# SERDES_10G0 register map
Vendor: Texas Instruments
Registers are 32-bit, read-write, reset 0x0 unless marked. A register's access mark holds for its fields unless they carry their own. Offsets are as the file gives them; [hi:lo] are bit positions.

## SERDES_10G0 (part 4 of 5)
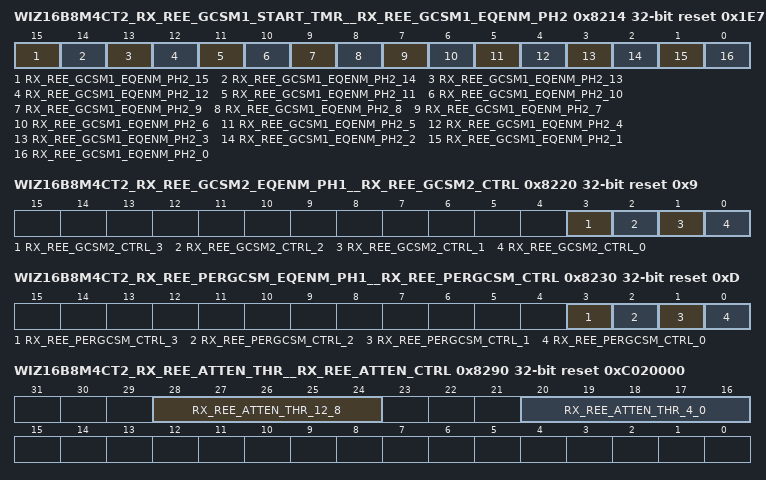
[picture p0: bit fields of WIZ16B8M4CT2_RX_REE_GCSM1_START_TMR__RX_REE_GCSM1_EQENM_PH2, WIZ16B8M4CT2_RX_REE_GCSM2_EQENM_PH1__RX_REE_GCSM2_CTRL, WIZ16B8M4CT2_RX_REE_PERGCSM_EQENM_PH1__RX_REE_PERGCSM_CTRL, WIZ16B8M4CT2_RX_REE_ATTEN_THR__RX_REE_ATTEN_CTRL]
0x8214 WIZ16B8M4CT2_RX_REE_GCSM1_START_TMR__RX_REE_GCSM1_EQENM_PH2 reset 0x1E7 — REE general control state machine 1 phase 2 equalization enable mask register
  [15] RX_REE_GCSM1_EQENM_PH2_15 — Reserved - spare
  [14] RX_REE_GCSM1_EQENM_PH2_14 — Ignore 1010 controller : When set to 1'b1, this function is enabled when the general control state machine 1 is controlling the REE.
  [13] RX_REE_GCSM1_EQENM_PH2_13 — TX equalization evaluator : When set to 1'b1, this function is enabled when the general control state machine 1 is controlling the REE.
  [12] RX_REE_GCSM1_EQENM_PH2_12 — TX post cursor control : When set to 1'b1, this function is enabled when the general control state machine 1 is controlling the REE.
  [11] RX_REE_GCSM1_EQENM_PH2_11 — TX pre cursor control : When set to 1'b1, this function is enabled when the general control state machine 1 is controlling the REE.
  [10] RX_REE_GCSM1_EQENM_PH2_10 — Short channel correction : When set to 1'b1, this function is enabled when the general control state machine 1 is controlling the REE.
  [9] RX_REE_GCSM1_EQENM_PH2_9 — RX attenuation : When set to 1'b1, this function is enabled when the general control state machine 1 is controlling the REE.
  [8] RX_REE_GCSM1_EQENM_PH2_8 — RX VGA gain : When set to 1'b1, this function is enabled when the general control state machine 1 is controlling the REE.
  [7] RX_REE_GCSM1_EQENM_PH2_7 — RX offset correction coefficient : When set to 1'b1, this function is enabled when the general control state machine 1 is controlling the REE.
  [6] RX_REE_GCSM1_EQENM_PH2_6 — RX peaking amp gain : When set to 1'b1, this function is enabled when the general control state machine 1 is controlling the REE.
  [5] RX_REE_GCSM1_EQENM_PH2_5 — RX low frequency equalizer adaptive control : When set to 1'b1, this function is enabled when the general control state machine 1 is controlling the REE.
  [4] RX_REE_GCSM1_EQENM_PH2_4 — Reserved - spare
  [3] RX_REE_GCSM1_EQENM_PH2_3 — Reserved - spare
  [2] RX_REE_GCSM1_EQENM_PH2_2 — RX tap 3 : When set to 1'b1, this function is enabled when the general control state machine 1 is controlling the REE.
  [1] RX_REE_GCSM1_EQENM_PH2_1 — RX tap 2 : When set to 1'b1, this function is enabled when the general control state machine 1 is controlling the REE.
  [0] RX_REE_GCSM1_EQENM_PH2_0 — RX tap 1 : When set to 1'b1, this function is enabled when the general control state machine 1 is controlling the REE.
0x8220 WIZ16B8M4CT2_RX_REE_GCSM2_EQENM_PH1__RX_REE_GCSM2_CTRL reset 0x9 — REE general control state machine 2 control register
  [3] RX_REE_GCSM2_CTRL_3 — Equalization function reset enable: Enables the reset of the functions controlled by this state machine, using the rx_ree_fcn_reset_n signal, when the equalization mode changes. 1'b1 : Enabled 1'b0 : Disabled
  [2] RX_REE_GCSM2_CTRL_2 — Loop enable: Controls when the equalization functions in this state machine are run one time or loop continuously.
  [1] RX_REE_GCSM2_CTRL_1 — Force run equalization: Setting this bit to a 1'b1, will force the general control state machine to run, independent of the macro functions that normally run the equalization.
  [0] RX_REE_GCSM2_CTRL_0 — Enable: This bit enables the general control state machine function. 1'b1 : Enabled 1'b0 : Disabled
0x8230 WIZ16B8M4CT2_RX_REE_PERGCSM_EQENM_PH1__RX_REE_PERGCSM_CTRL reset 0xD — REE periodic general control state machine control register
  [3] RX_REE_PERGCSM_CTRL_3 — Equalization function reset enable: Enables the reset of the functions controlled by this state machine, using the rx_ree_fcn_reset_n pin, when the equalization mode changes. 1'b1 : Enabled 1'b0 : Disabled
  [2] RX_REE_PERGCSM_CTRL_2 — Loop enable: Controls when the equalization functions in this state machine are run one time or loop continuously.
  [1] RX_REE_PERGCSM_CTRL_1 — Force run equalization: Setting this bit to a 1'b1, will force the general control state machine to run, independent of the macro functions that normally run the equalization.
  [0] RX_REE_PERGCSM_CTRL_0 — Enable: This bit enables the general control state machine function. 1'b1 : Enabled 1'b0 : Disabled
0x8290 WIZ16B8M4CT2_RX_REE_ATTEN_THR__RX_REE_ATTEN_CTRL reset 0xC020000 — REE attenuation control register (!)
  [28:24] RX_REE_ATTEN_THR_12_8 — Attenuation high threshold value: High threshold value to compare against the VGA gain accumulator value. Note that the value on this field is not a twos complement value (There is no sign bit and it is always a positive number).
  [20:16] RX_REE_ATTEN_THR_4_0 — Attenuation low threshold value: Low threshold value to compare against the VGA gain accumulator value. Note that the value on this field is not a twos complement value (There is no sign bit and it is always a positive number).
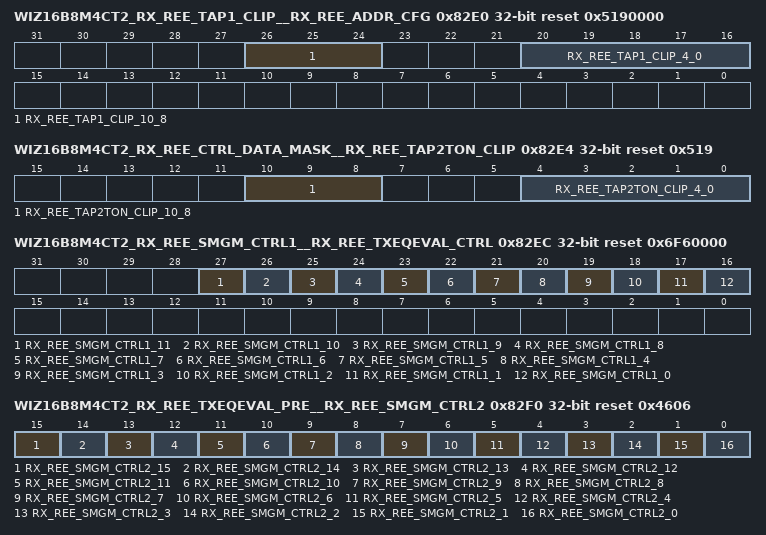
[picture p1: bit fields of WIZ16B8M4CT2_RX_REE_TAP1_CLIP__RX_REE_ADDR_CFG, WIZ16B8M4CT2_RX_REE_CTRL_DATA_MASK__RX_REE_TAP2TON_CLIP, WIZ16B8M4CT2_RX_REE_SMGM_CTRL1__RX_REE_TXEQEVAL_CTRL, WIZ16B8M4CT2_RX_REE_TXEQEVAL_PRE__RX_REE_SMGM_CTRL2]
0x82E0 WIZ16B8M4CT2_RX_REE_TAP1_CLIP__RX_REE_ADDR_CFG reset 0x5190000 — REE adder configuration register (!)
  [26:24] RX_REE_TAP1_CLIP_10_8 — VGA target gain adjust multiplier: Controls how much to multiply the VGA target gain adjust by, when calculating the tap threshold. The following are valid values, and the corresponding multiplier values. 3'b000 : x 0.00 3'b001 : x 0.25 3'b010 : x 0.50 3'b011 : x 0.75 3'b100 : x 1.00 3'b101 : x 1.25 3'b110 : x 1.50 3'b111 : x 1.75 Note : By setting this field to 3'b000, the threshold value of the tap can be directly controlled by the threshold adjust field in this register. Note : The VGA gain adjust signal is always a negative number.
  [20:16] RX_REE_TAP1_CLIP_4_0 — Threshold adjust: Controls how much the threshold can be adjusted by, after multiplying the VGA target gain adjust multiplier with the VGA target gain adjust. Note that this field is a positive number (not twos complement). Note : This field must not be set to a value of 0. Note : The combination of the multiplier and threshold fields in this register controls the positive and negative thresholds for the taps, according to the following equation. Note that the logic associated with this limits the range of the magnitude to 0 to 31, before creating the positive and negative thresholds. +/- ((VGA target gain adjust * VGA target gain adjust multiplier) + Threshold adjust)
0x82E4 WIZ16B8M4CT2_RX_REE_CTRL_DATA_MASK__RX_REE_TAP2TON_CLIP reset 0x519 — REE taps 2 and 3 clip control register (!)
  [10:8] RX_REE_TAP2TON_CLIP_10_8 — VGA target gain adjust multiplier: Controls how much to multiply the VGA target gain adjust by, when calculating the tap threshold. The following are valid values, and the corresponding multiplier values. 3'b000 : x 0.00 3'b001 : x 0.25 3'b010 : x 0.50 3'b011 : x 0.75 3'b100 : x 1.00 3'b101 : x 1.25 3'b110 : x 1.50 3'b111 : x 1.75 Note : By setting this field to 3'b000, the threshold value of the tap can be directly controlled by the threshold adjust field in this register.
  [4:0] RX_REE_TAP2TON_CLIP_4_0 — Threshold adjust: Controls how much the threshold can be adjusted by, after multiplying the VGA target gain adjust multiplier with the VGA target gain adjust. Note that this field is a positive number (not twos complement). Note : This field must not be set to a value of 0. Note : The combination of the multiplier and threshold fields in this register controls the positive and negative thresholds for the taps, according to the following equation. Note that the logic associated with this limits the range of the magnitude to 0 to 31, before creating the positive and negative thresholds. +/- ((VGA target gain adjust * VGA target gain adjust multiplier) + Threshold adjust)
0x82EC WIZ16B8M4CT2_RX_REE_SMGM_CTRL1__RX_REE_TXEQEVAL_CTRL reset 0x6F60000 — REE TX equalization evaluator control register (!)
  [27] RX_REE_SMGM_CTRL1_11 — REE Periodic general control state machine enable standard mode 3: This bit will control if the REE periodic general control state machine will run, when xcvr_standard_mode is set to 2'b11. 1'b0 : Disabled 1'b1 : Enabled
  [26] RX_REE_SMGM_CTRL1_10 — REE Periodic general control state machine enable standard mode 2: This bit will control if the REE periodic general control state machine will run, when xcvr_standard_mode is set to 2'b10. 1'b0 : Disabled 1'b1 : Enabled
  [25] RX_REE_SMGM_CTRL1_9 — REE Periodic general control state machine enable standard mode 1: This bit will control if the REE periodic general control state machine will run, when xcvr_standard_mode is set to 2'b01. 1'b0 : Disabled 1'b1 : Enabled
  [24] RX_REE_SMGM_CTRL1_8 — REE Periodic general control state machine enable standard mode 0: This bit will control if the REE periodic general control state machine will run, when xcvr_standard_mode is set to 2'b00. 1'b0 : Disabled 1'b1 : Enabled
  [23] RX_REE_SMGM_CTRL1_7 — REE general control state machine 2 enable standard mode 3: This bit will control if the REE general control state machine 2 will run, when xcvr_standard_mode is set to 2'b11. 1'b0 : Disabled 1'b1 : Enabled
  [22] RX_REE_SMGM_CTRL1_6 — REE general control state machine 2 enable standard mode 2: This bit will control if the REE general control state machine 2 will run, when xcvr_standard_mode is set to 2'b10. 1'b0 : Disabled 1'b1 : Enabled
  [21] RX_REE_SMGM_CTRL1_5 — REE general control state machine 2 enable standard mode 1: This bit will control if the REE general control state machine 2 will run, when xcvr_standard_mode is set to 2'b01. 1'b0 : Disabled 1'b1 : Enabled
  [20] RX_REE_SMGM_CTRL1_4 — REE general control state machine 2 enable standard mode 0: This bit will control if the REE general control state machine 2 will run, when xcvr_standard_mode is set to 2'b00. 1'b0 : Disabled 1'b1 : Enabled
  [19] RX_REE_SMGM_CTRL1_3 — REE general control state machine 1 enable standard mode 3: This bit will control if the REE general control state machine 1 will run, when xcvr_standard_mode is set to 2'b11. 1'b0 : Disabled 1'b1 : Enabled
  [18] RX_REE_SMGM_CTRL1_2 — REE general control state machine 1 enable standard mode 2: This bit will control if the REE general control state machine 1 will run, when xcvr_standard_mode is set to 2'b10. 1'b0 : Disabled 1'b1 : Enabled
  [17] RX_REE_SMGM_CTRL1_1 — REE general control state machine 1 enable standard mode 1: This bit will control if the REE general control state machine 1 will run, when xcvr_standard_mode is set to 2'b01. 1'b0 : Disabled 1'b1 : Enabled
  [16] RX_REE_SMGM_CTRL1_0 — REE general control state machine 1 enable standard mode 0: This bit will control if the REE general control state machine 1 will run, when xcvr_standard_mode is set to 2'b00. 1'b0 : Disabled 1'b1 : Enabled
0x82F0 WIZ16B8M4CT2_RX_REE_TXEQEVAL_PRE__RX_REE_SMGM_CTRL2 reset 0x4606 — REE control state machine gen mode control register 2 (!)
  [15] RX_REE_SMGM_CTRL2_15 — REE PCIe Gen 3 TX equalization state machine E path en standard mode 3: This bit controls if the REE PCIE Gen 3 TX equalization state machine will enable the analog E path when xcvr_standard_mode is set to 2'b11. 1'b0 : Disabled 1'b1 : Enabled
  [14] RX_REE_SMGM_CTRL2_14 — REE PCIe Gen 3 TX equalization state machine E path en standard mode 2: This bit controls if the REE PCIE Gen 3 TX equalization state machine will enable the analog E path when xcvr_standard_mode is set to 2'b10. 1'b0 : Disabled 1'b1 : Enabled
  [13] RX_REE_SMGM_CTRL2_13 — REE PCIe Gen 3 TX equalization state machine E path en standard mode 1: This bit controls if the REE PCIE Gen 3 TX equalization state machine will enable the analog E path when xcvr_standard_mode is set to 2'b01. 1'b0 : Disabled 1'b1 : Enabled
  [12] RX_REE_SMGM_CTRL2_12 — REE PCIe Gen 3 TX equalization state machine E path en standard mode 0: This bit controls if the REE PCIE Gen 3 TX equalization state machine will enable the analog E path when xcvr_standard_mode is set to 2'b00. 1'b0 : Disabled 1'b1 : Enabled
  [11] RX_REE_SMGM_CTRL2_11 — REE Periodic general control state machine E path en standard mode 3: This bit controls if the REE periodic general control state machine will enable the analog E path when xcvr_standard_mode is set to 2'b11. 1'b0 : Disabled 1'b1 : Enabled
  [10] RX_REE_SMGM_CTRL2_10 — REE Periodic general control state machine E path en standard mode 2: This bit controls if the REE periodic general control state machine will enable the analog E path when xcvr_standard_mode is set to 2'b10. 1'b0 : Disabled 1'b1 : Enabled
  [9] RX_REE_SMGM_CTRL2_9 — REE Periodic general control state machine E path en standard mode 1: This bit controls if the REE periodic general control state machine will enable the analog E path when xcvr_standard_mode is set to 2'b01. 1'b0 : Disabled 1'b1 : Enabled
  [8] RX_REE_SMGM_CTRL2_8 — REE Periodic general control state machine E path en standard mode 0: This bit controls if the REE periodic general control state machine will enable the analog E path when xcvr_standard_mode is set to 2'b00. 1'b0 : Disabled 1'b1 : Enabled
  [7] RX_REE_SMGM_CTRL2_7 — REE general control state machine 2 E path en standard mode 3: This bit controls if the REE general control state machine 2 will enable the analog E path when xcvr_standard_mode is set to 2'b11. 1'b0 : Disabled 1'b1 : Enabled
  [6] RX_REE_SMGM_CTRL2_6 — REE general control state machine 2 E path en standard mode 2: This bit controls if the REE general control state machine 2 will enable the analog E path when xcvr_standard_mode is set to 2'b10. 1'b0 : Disabled 1'b1 : Enabled
  [5] RX_REE_SMGM_CTRL2_5 — REE general control state machine 2 E path en standard mode 1: This bit controls if the REE general control state machine 2 will enable the analog E path when xcvr_standard_mode is set to 2'b01. 1'b0 : Disabled 1'b1 : Enabled
  [4] RX_REE_SMGM_CTRL2_4 — REE general control state machine 2 E path en standard mode 0: This bit controls if the REE general control state machine 2 will enable the analog E path when xcvr_standard_mode is set to 2'b00. 1'b0 : Disabled 1'b1 : Enabled
  [3] RX_REE_SMGM_CTRL2_3 — REE general control state machine 1 E path en standard mode 3: This bit controls if the REE general control state machine 1 will enable the analog E path when xcvr_standard_mode is set to 2'b11. 1'b0 : Disabled 1'b1 : Enabled
  [2] RX_REE_SMGM_CTRL2_2 — REE general control state machine 1 E path en standard mode 2: This bit controls if the REE general control state machine 1 will enable the analog E path when xcvr_standard_mode is set to 2'b10. 1'b0 : Disabled 1'b1 : Enabled
  [1] RX_REE_SMGM_CTRL2_1 — REE general control state machine 1 E path en standard mode 1: This bit controls if the REE general control state machine 1 will enable the analog E path when xcvr_standard_mode is set to 2'b01. 1'b0 : Disabled 1'b1 : Enabled
  [0] RX_REE_SMGM_CTRL2_0 — REE general control state machine 1 E path en standard mode 0: This bit controls if the REE general control state machine 1 will enable the analog E path when xcvr_standard_mode is set to 2'b00. 1'b0 : Disabled 1'b1 : Enabled
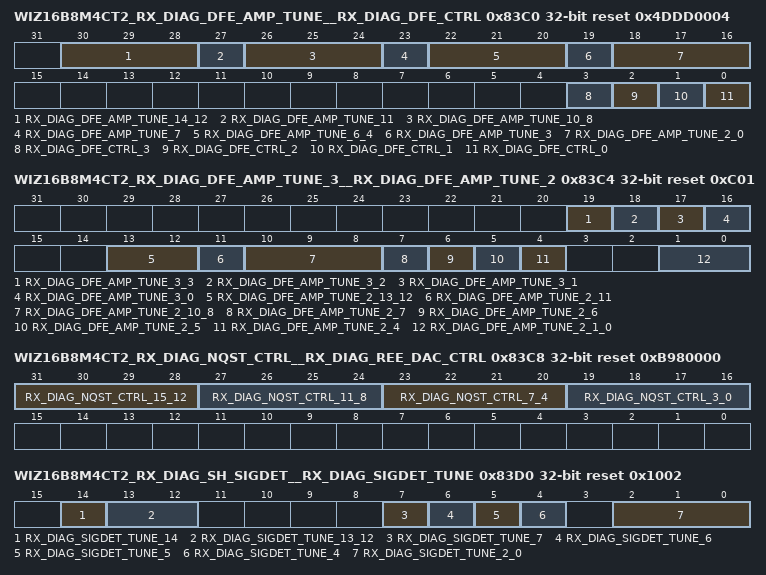
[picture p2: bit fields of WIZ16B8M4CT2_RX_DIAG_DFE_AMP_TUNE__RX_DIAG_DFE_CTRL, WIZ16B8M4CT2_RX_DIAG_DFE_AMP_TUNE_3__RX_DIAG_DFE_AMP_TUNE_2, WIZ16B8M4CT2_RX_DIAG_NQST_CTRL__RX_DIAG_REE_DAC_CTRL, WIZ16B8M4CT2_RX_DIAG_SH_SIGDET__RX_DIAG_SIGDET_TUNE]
0x83C0 WIZ16B8M4CT2_RX_DIAG_DFE_AMP_TUNE__RX_DIAG_DFE_CTRL reset 0x4DDD0004 — Receiver DFE control register (!)
  [30:28] RX_DIAG_DFE_AMP_TUNE_14_12 — DFE constant gm bias tune: Adjusts the constant gm bias. 3'b000: -34 uA 3'b001 3'b010 3'b011 3'b100: - 50 uA 3'b101 3'b110 3'b111: -62 uA
  [27] RX_DIAG_DFE_AMP_TUNE_11 — DFE VGA constant gm bias enable: Enables the VGA constant gm bias. This bit drives the rxda_vga_cnst_gm_en signal going to the analog. 1'b0 : Disabled. 1'b1 : Enabled.
  [26:24] RX_DIAG_DFE_AMP_TUNE_10_8 — DFE VGA amp current adjust: Adjusts the current for the DFE VGA amp, using the rxda_vga_current_adj signal, as specified below. Note that the percentages are approximate values. 3'b000: +30% (maximum) ... 3'b101: 0% ... 3'b111: -30% (minimum)
  [23] RX_DIAG_DFE_AMP_TUNE_7 — DFE peaking constant gm bias enable: Enables the peaking constant gm bias. This bit drives the rxda_peak_cnst_gm_en signal going to the analog. 1'b0 : Disabled. 1'b1 : Enabled.
  [22:20] RX_DIAG_DFE_AMP_TUNE_6_4 — DFE peaking amp current adjust: Adjusts the current for the DFE peaking amp, using the rxda_peak_current_adj signal, as specified below. Note that the percentages are approximate values. 3'b000: +30% (maximum) ... 3'b101: 0% ... 3'b111: -30% (minimum)
  [19] RX_DIAG_DFE_AMP_TUNE_3 — DFE summing constant gm bias enable: Enables the summing constant gm bias. This bit drives the rxda_sum_cnst_gm_en signal going to the analog. 1'b0 : Disabled. 1'b1 : Enabled.
  [18:16] RX_DIAG_DFE_AMP_TUNE_2_0 — DFE summing amp current adjust: Adjusts the current for the DFE summing amp, using the rxda_sum_current_adj signal, as specified below. Note that the percentages are approximate values. 3'b000: +30% (maximum) ... 3'b101: 0% ... 3'b111: -30% (minimum)
  [3] RX_DIAG_DFE_CTRL_3 — Receiver DFE low frequency equalization enable value standard mode 3: This bit controls the rxda_dfe_lfeq_en signal going to the analog, which is used to enable the receiver DFE low frequency equalization analog circuits, when xcvr_standard_mode is set to 2'b11. 1'b0 : Disabled 1'b1 : Enabled
  [2] RX_DIAG_DFE_CTRL_2 — Receiver DFE low frequency equalization enable value standard mode 2: This bit controls the rxda_dfe_lfeq_en signal going to the analog, which is used to enable the receiver DFE low frequency equalization analog circuits, when xcvr_standard_mode is set to 2'b10. 1'b0 : Disabled 1'b1 : Enabled
  [1] RX_DIAG_DFE_CTRL_1 — Receiver DFE low frequency equalization enable value standard mode 1: This bit controls the rxda_dfe_lfeq_en signal going to the analog, which is used to enable the receiver DFE low frequency equalization analog circuits, when xcvr_standard_mode is set to 2'b01. 1'b0 : Disabled 1'b1 : Enabled
  [0] RX_DIAG_DFE_CTRL_0 — Receiver DFE low frequency equalization enable value standard mode 0: This bit controls the rxda_dfe_lfeq_en signal going to the analog, which is used to enable the receiver DFE low frequency equalization analog circuits, when xcvr_standard_mode is set to 2'b00. 1'b0 : Disabled 1'b1 : Enabled
0x83C4 WIZ16B8M4CT2_RX_DIAG_DFE_AMP_TUNE_3__RX_DIAG_DFE_AMP_TUNE_2 reset 0xC01 — DFE amp fine tuning 2 register (!)
  [19] RX_DIAG_DFE_AMP_TUNE_3_3 — DFE VGA stage 1 boost standard mode 3: This bit enables the active inductors boost function in stage 1 of the VGA, for high data rates, when xcvr_standard_mode is set to 2'b11. This bit controls the rxda_vga_st1_actind_en signal going to the analog. 1'b0 : Disabled 1'b1 : Enabled
  [18] RX_DIAG_DFE_AMP_TUNE_3_2 — DFE VGA stage 1 boost standard mode 2: This bit enables the active inductors boost function in stage 1 of the VGA, for high data rates, when xcvr_standard_mode is set to 2'b10. This bit controls the rxda_vga_st1_actind_en signal going to the analog. 1'b0 : Disabled 1'b1 : Enabled
  [17] RX_DIAG_DFE_AMP_TUNE_3_1 — DFE VGA stage 1 boost standard mode 1: This bit enables the active inductors boost function in stage 1 of the VGA, for high data rates, when xcvr_standard_mode is set to 2'b01. This bit controls the rxda_vga_st1_actind_en signal going to the analog. 1'b0 : Disabled 1'b1 : Enabled
  [16] RX_DIAG_DFE_AMP_TUNE_3_0 — DFE VGA stage 1 boost standard mode 0: This bit enables the active inductors boost function in stage 1 of the VGA, for high data rates, when xcvr_standard_mode is set to 2'b00. This bit controls the rxda_vga_st1_actind_en signal going to the analog. 1'b0 : Disabled 1'b1 : Enabled
  [13:12] RX_DIAG_DFE_AMP_TUNE_2_13_12 — Receiver peaking amp common mode adjust: Adjusts the common mode voltage for the receiver peaking amp, by driving the rxda_fe_pkamp_cm_adj signal to the analog. 2'b00 : Nominal common mode voltage. 2'b01 : Reduces the common mode voltage by one step. 2'b10 : Increases the common mode voltage by one step. 2'b11 : Reserved
  [11] RX_DIAG_DFE_AMP_TUNE_2_11 — DFE low frequency equalizer constant gm bias enable: Enables the low frequency equalizer constant gm bias. This bit drives the rxda_lfeq_cnst_gm_en signal going to the analog. 1'b0 : Disabled. 1'b1 : Enabled.
  [10:8] RX_DIAG_DFE_AMP_TUNE_2_10_8 — DFE low frequency equalizer current adjust: Adjusts the current for the DFE low frequency equalizer, using the rxda_lfeq_current_adj signal, as specified below. Note that the percentages are approximate values. 3'b000: +30% (maximum) ... 3'b101: 0% ... 3'b111: -30% (minimum)
  [7] RX_DIAG_DFE_AMP_TUNE_2_7 — DFE peaking amp boost: Enables the active inductors boost function in the peaking amp, for high data rates. This bit controls the rxda_peak_actind_en signal going to the analog. 1'b0 : Disabled 1'b1 : Enabled
  [6] RX_DIAG_DFE_AMP_TUNE_2_6 — Reserved - Spare
  [5] RX_DIAG_DFE_AMP_TUNE_2_5 — DFE VGA stage 2 boost: Enables the active inductors boost function in stage 2 of the VGA, for high data rates. This bit controls the rxda_vga_st2_actind_en signal going to the analog. 1'b0 : Disabled 1'b1 : Enabled
  [4] RX_DIAG_DFE_AMP_TUNE_2_4 — DFE RX Tap 1 DAC Range Select: Controls the tap 1 DAC range in the analog DFE. This bit controls the rxda_dfe_tap_1_range signal going to the analog. 1'b0: Normal operation 1'b1: The tap 1 DAC range is increased.
  [1:0] RX_DIAG_DFE_AMP_TUNE_2_1_0 — DFE RX amp current adjust: Adjusts the mix of constant-gm and External Current for RX front end amplifiers. This controls the rxda_cnstgm_ext_sel signal going into the analog. The encoding of the rxda_cnstgm_ext_sel signal, as a function of the values in this register is specified below. 2'b00 =X 3'b000 : gm_bias = 25u, ext = 25u, total = 50u 2'b01 =X 3'b001 : gm_bias = 30u, ext = 20u, total = 50u 2'b10 =X 3'b011 : gm_bias = 35u, ext = 15u, total = 50u 2'b11 =X 3'b111 : gm_bias = 40u, ext = 10u, total = 50u
0x83C8 WIZ16B8M4CT2_RX_DIAG_NQST_CTRL__RX_DIAG_REE_DAC_CTRL reset 0xB980000 — REE DAC control register (!)
  [31:28] RX_DIAG_NQST_CTRL_15_12 — RX nyquist select value standard mode 3: This field specifies the receiver DFE nyquist frequency select value on the rxda_dfe_nqst_sel signal driven to the analog, when xcvr_standard_mode is set to 2'b11.
  [27:24] RX_DIAG_NQST_CTRL_11_8 — RX nyquist select value standard mode 2: This field specifies the receiver DFE nyquist frequency select value on the rxda_dfe_nqst_sel signal driven to the analog, when xcvr_standard_mode is set to 2'b10.
  [23:20] RX_DIAG_NQST_CTRL_7_4 — RX nyquist select value standard mode 1: This field specifies the receiver DFE nyquist frequency select value on the rxda_dfe_nqst_sel signal driven to the analog, when xcvr_standard_mode is set to 2'b01.
  [19:16] RX_DIAG_NQST_CTRL_3_0 — RX nyquist select value standard mode 0: This field specifies the receiver DFE nyquist frequency select value on the rxda_dfe_nqst_sel signal driven to the analog, when xcvr_standard_mode is set to 2'b00.
0x83D0 WIZ16B8M4CT2_RX_DIAG_SH_SIGDET__RX_DIAG_SIGDET_TUNE reset 0x1002 — RX signal detect tuning and control register (!)
  [14] RX_DIAG_SIGDET_TUNE_14 — Signal detect calibration half gain select: Controls the resolution of each step in the signal detect calibration code by adjusting the gain of signal detect offset correction, by driving the rxda_sd_cal_halfgain signal going to the analog, as specified below. 1'b0: 8mV resolution per calibration code step. 1'b1: 4mV resolution per calibration code step.
  [13:12] RX_DIAG_SIGDET_TUNE_13_12 — Signal detect filter function select: Selects which of the two RX signal detect filter functions are enabled. As specified below. 2'b00 : Reserved 2'b01 : RX low to high filter disabled, RX high to low filter enabled. 2'b10 : RX low to high filter enabled, RX high to low filter disabled. 2'b11 : RX low to high filter enabled, RX high to low filter enabled.
  [7] RX_DIAG_SIGDET_TUNE_7 — Receiver signal detect invert samplers: Inverts the behavior of the rxda_sd_pulse_high and rxda_sd_pulse_low samplers, by driving the rxda_sd_invert_samplers signal to the analog. 1'b0 : Normal mode : The rxda_sd_pulse_high sampler outputs a 1'b1 if the output of the comparator has been above the positive threshold at any time during the last clock period. Similar behavior exists for the rxda_sd_pulse_low sampler in this mode. 1'b1 : Inverted mode : The rxda_sd_pulse_high sampler outputs a 1'b1 if the output of the comparator has been above the positive threshold for the entire duration of the last clock period. Similar behavior exists for the rxda_sd_pulse_low sampler in this mode.
  [6] RX_DIAG_SIGDET_TUNE_6 — Receiver signal detect squelch pulse none: Enable the squelch function for the rxda_sd_pulse_none signal, by driving the rxda_sd_squelch_pulse_none signal to the analog. This debug feature could allow the detection of LFPS signals having slow transition times (e.g. 4 nSec) and low frequency differential noise (e.g. 500 MHz). The later can create noise glitches taking place over man than 1/2 cycle when DCD is taken into consideration. 1'b0 : Disabled 1'b1 : Enabled
  [5] RX_DIAG_SIGDET_TUNE_5 — Receiver signal detect one comparator mode: Enables one comparator mode, as a power reduction option, by driving the rxda_sd_onecomp_mode_en signal to the analog. 1'b0 : Both signal detect comparators functioning. 1'b1 : One signal detect comparator functioning.
  [4] RX_DIAG_SIGDET_TUNE_4 — Receiver signal detect DC coupled path enable: Enables a DC coupled path to the signal detect for verification and testability purposes, by driving the rxda_sd_dcpath_en signal to the analog. 1'b0 : Disabled 1'b1 : Enabled
  [2:0] RX_DIAG_SIGDET_TUNE_2_0 — Signal detect level: Sets the reference voltage level at which the comparators will detect a signal by driving the rxda_sd_siglvl_n signal going to the analog. The following specifies the encoding of this signal. 3'b000 : 8'b11111110 : Min 3'b001 : 8'b11111101 ... 3'b110 : 8'b10111111 3'b111 : 8'b01111111 : Max
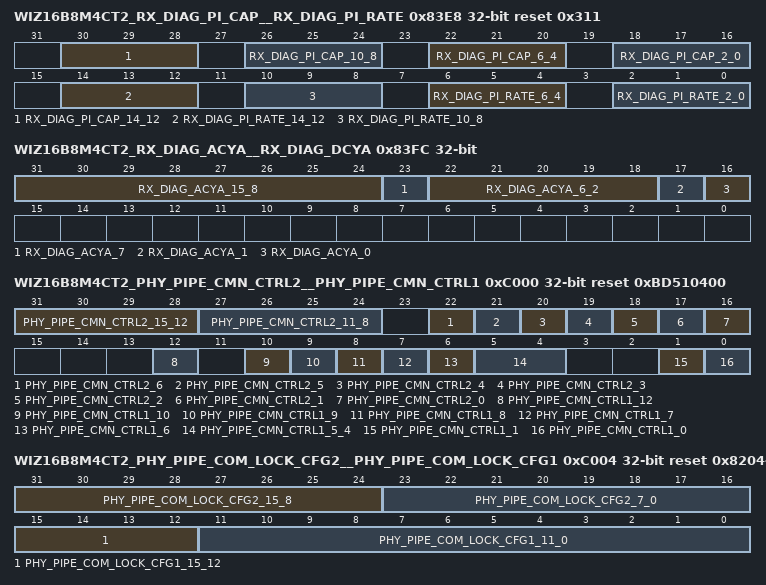
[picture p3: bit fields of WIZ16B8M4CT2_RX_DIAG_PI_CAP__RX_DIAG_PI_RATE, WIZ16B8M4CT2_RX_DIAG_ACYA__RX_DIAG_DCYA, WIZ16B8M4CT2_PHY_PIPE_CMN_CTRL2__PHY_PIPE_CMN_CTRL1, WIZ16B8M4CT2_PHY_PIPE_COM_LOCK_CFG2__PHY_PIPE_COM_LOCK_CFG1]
0x83E8 WIZ16B8M4CT2_RX_DIAG_PI_CAP__RX_DIAG_PI_RATE reset 0x311 — PI rate selection register (!)
  [30:28] RX_DIAG_PI_CAP_14_12 — PI capacitor selection standard mode 3: This field is used to implement waveform shaping inside the PI CML cells, by changing the capacitive loading. As the data rate decreases, this is used to increase cap loading, to maintain semi-sinusoidal wave shapes inside the PI CML input buffers and mixers, by driving the rxda_pi_cap_sel signal going into the analog, when xcvr_standard_mode is set to 2'b11. The following is the encoding of this field. 3'b000: Default capacitance required for wave shaping for data rates at 2.5G and higher. 3'b001: Increased capacitance required for wave shaping for data rates below 2.5G. 3'b010 - 3'b111: Reserved
  [26:24] RX_DIAG_PI_CAP_10_8 — PI capacitor selection standard mode 2: This field is used to implement waveform shaping inside the PI CML cells, by changing the capacitive loading. As the data rate decreases, this is used to increase cap loading, to maintain semi-sinusoidal wave shapes inside the PI CML input buffers and mixers, by driving the rxda_pi_cap_sel signal going into the analog, when xcvr_standard_mode is set to 2'b10. The following is the encoding of this field. 3'b000: Default capacitance required for wave shaping for data rates at 2.5G and higher. 3'b001: Increased capacitance required for wave shaping for data rates below 2.5G. 3'b010 - 3'b111: Reserved
  [22:20] RX_DIAG_PI_CAP_6_4 — PI capacitor selection standard mode 1: This field is used to implement waveform shaping inside the PI CML cells, by changing the capacitive loading. As the data rate decreases, this is used to increase cap loading, to maintain semi-sinusoidal wave shapes inside the PI CML input buffers and mixers, by driving the rxda_pi_cap_sel signal going into the analog, when xcvr_standard_mode is set to 2'b01. The following is the encoding of this field. 3'b000: Default capacitance required for wave shaping for data rates at 2.5G and higher. 3'b001: Increased capacitance required for wave shaping for data rates below 2.5G. 3'b010 - 3'b111: Reserved
  [18:16] RX_DIAG_PI_CAP_2_0 — PI capacitor selection standard mode 0: This field is used to implement waveform shaping inside the PI CML cells, by changing the capacitive loading. As the data rate decreases, this is used to increase cap loading, to maintain semi-sinusoidal wave shapes inside the PI CML input buffers and mixers, by driving the rxda_pi_cap_sel signal going into the analog, when xcvr_standard_mode is set to 2'b00. The following is the encoding of this field. 3'b000: Default capacitance required for wave shaping for data rates at 2.5G and higher. 3'b001: Increased capacitance required for wave shaping for data rates below 2.5G. 3'b010 - 3'b111: Reserved
  [14:12] RX_DIAG_PI_RATE_14_12 — PI rate selection standard mode 3: This field is used to scale the power of the CML cells inside the PI to tune it for a given data rate, by driving the rxda_pi_rate_sel signal going into the analog, when xcvr_standard_mode is set to 2'b11. The following is the encoding of this field. 3'b000: 1/2X power scaling for the CML cells. This should be the default setting for 2.5G data rates. 3'b001:1X power scaling for the CML cells. This should be the default setting for 5G data rates. 3'b010: Reserved 3'b011: 2X power scaling for the CML cells. This should be the default setting for 10G data rates. 3'b100 - 3'b111: Reserved
  [10:8] RX_DIAG_PI_RATE_10_8 — PI rate selection standard mode 2: This field is used to scale the power of the CML cells inside the PI to tune it for a given data rate, by driving the rxda_pi_rate_sel signal going into the analog, when xcvr_standard_mode is set to 2'b10. The following is the encoding of this field. 3'b000: 1/2X power scaling for the CML cells. This should be the default setting for 2.5G data rates. 3'b001:1X power scaling for the CML cells. This should be the default setting for 5G data rates. 3'b010: Reserved 3'b011: 2X power scaling for the CML cells. This should be the default setting for 10G data rates. 3'b100 - 3'b111: Reserved
  [6:4] RX_DIAG_PI_RATE_6_4 — PI rate selection standard mode 1: This field is used to scale the power of the CML cells inside the PI to tune it for a given data rate, by driving the rxda_pi_rate_sel signal going into the analog, when xcvr_standard_mode is set to 2'b01. The following is the encoding of this field. 3'b000: 1/2X power scaling for the CML cells. This should be the default setting for 2.5G data rates. 3'b001:1X power scaling for the CML cells. This should be the default setting for 5G data rates. 3'b010: Reserved 3'b011: 2X power scaling for the CML cells. This should be the default setting for 10G data rates. 3'b100 - 3'b111: Reserved
  [2:0] RX_DIAG_PI_RATE_2_0 — PI rate selection standard mode 0: This field is used to scale the power of the CML cells inside the PI to tune it for a given data rate, by driving the rxda_pi_rate_sel signal going into the analog, when xcvr_standard_mode is set to 2'b00. The following is the encoding of this field. 3'b000: 1/2X power scaling for the CML cells. This should be the default setting for 2.5G data rates. 3'b001:1X power scaling for the CML cells. This should be the default setting for 5G data rates. 3'b010: Reserved 3'b011: 2X power scaling for the CML cells. This should be the default setting for 10G data rates. 3'b100 - 3'b111: Reserved
0x83FC WIZ16B8M4CT2_RX_DIAG_ACYA__RX_DIAG_DCYA — Receiver digital cover your alternatives register (!)
  [31:24] RX_DIAG_ACYA_15_8 — Reserved - spare
  [23] RX_DIAG_ACYA_7 — Serial loopback sampler setup time reduction select (TX only lane implementation): For TX only lane implementations, this bit can be used to reduce the setup time (providing more hold margin) for the serial loopback data. This function is in place, in case there are unexpected timing issues, due to the lack of a CDRLF in the transmit only lane implementations. 1'b0: Default setup time 1'b1: Reduced setup time
  [22:18] RX_DIAG_ACYA_6_2 — Reserved - spare
  [17] RX_DIAG_ACYA_1 — Force receiver signal detect clock enable: This bit is used to force the receiver signal detect clock (rxda_sd_clk) driven from the analog to be enabled, independent of whether the analog signal detect function is enabled or not. 1'b0: Clock not forced to be enabled 1'b1: Clock forced to be enabled
  [16] RX_DIAG_ACYA_0 — Full rate clock duty cycle correction enable: Enables the analog duty cycle correction function for the full rate clock that drives the divide by 2 circuit to generate the half rate I and Q clocks. 1'b0: Enabled 1'b1: Disabled
0xA000 WIZ16B8M4CT2_RESERVEDBIT13ADDRESSC — Reserved Address bit 13 area C
  [31:0] RES_BIT13_ADR_C — Write only test region C
0xC000 WIZ16B8M4CT2_PHY_PIPE_CMN_CTRL2__PHY_PIPE_CMN_CTRL1 access not given reset 0xBD510400 — PIPE common control1 register
  [31:28] PHY_PIPE_CMN_CTRL2_15_12 rw — USB SuperSpeed Tx LFPS Stretch : Minimum number of data rate clock cycles in which PMA tx_lfps_en signal is asserted for USB SuperSpeed rate. Number of data rate clock cycles must be X 1 PMA RefClk cycle.
  [27:24] PHY_PIPE_CMN_CTRL2_11_8 rw — USB SuperSpeedPlus Tx LFPS Stretch : Minimum number of data rate clock cycles in which PMA tx_lfps_en signal is asserted for USB SuperSpeedPlus rate. Number of data rate clock cycles must be X 1 PMA RefClk cycle.
  [22] PHY_PIPE_CMN_CTRL2_6 rw — PCIe PCS TX electrical idle pre release:When this bit is set, the TX electrical idle release to the PMA is advanced 1 cycle to allow the adjustment of the datapath timing
  [21] PHY_PIPE_CMN_CTRL2_5 rw — RX equaliser complete mask: When this bit is cleared, the PHY will return direction change of 0 when PMA indicates evaluation complete. Subsequent evaluation requests would clear the PMA iteration counters. When set high, the PMA equalization complete signal is ignored.
  [20] PHY_PIPE_CMN_CTRL2_4 rw — PCIe PCS EIOS cycle error mask: When this bit is enabled and the pipe rx interface is outputting an EIOS symbol, decode errors will be masked out
  [19] PHY_PIPE_CMN_CTRL2_3 rw — USB Gen 2 Bit Error Correction Disable: When this bit is high, bit error correction on SKP and SDS symbols is disabled.
  [18] PHY_PIPE_CMN_CTRL2_2 rw — USB PIPE3 Compatibility Mode enable : When this bit is set to 1, USB PIPE3 compatibility mode is enabled. In this mode, when operating in nominal empty Elasticity Buffer mode, when the EB buffer goes empty, instead of de-asserting PIPE RxDataValid, a USB SKIP OS is inserted into the data stream. This is the behavior as defined in PIPE version 3. When this bit is low, PIPE RxDataValid is de-asserted when the EB buffer goes empty, as recommended by PIPE version 4.
  [17] PHY_PIPE_CMN_CTRL2_1 rw — USB Loopback Slave Error Count disable: When this bit is set to 1, disables the error count for US loopback slave, such that the error count is not inserted into the BCNT OS.
  [16] PHY_PIPE_CMN_CTRL2_0 rw — USB Elasticity Buffer Re-align enable: When this bit is set to 1, when Rx for a USB link is initially started, the elasticity buffer is re-aligned to its idle point upon seeing 3 consecutive COMMAs (i.e. from TS1/TS2s) in the same relative bit position. The purpose of this is to re-align the elasticity buffer (i.e. CTC) after receiving the TSEQ data, which contains no SKIP OSs.
  [12] PHY_PIPE_CMN_CTRL1_12 — PHY APB access timeout: When set, an APB read/write request to PHY registers failed (i.e. timed out). When set, this bit is cleared upon read. (access RTR)
  [10] PHY_PIPE_CMN_CTRL1_10 rw — PCIe PCS Comma realign: This field controls the comma alignment state machine to re-align to new bit position without going to loss of sync state. The requirement of the new bit position should meet the number of COMMAs as per Symbol unlock count register definition. When new bit position is identified the comma alignment state machine remains in sync state with the alignment now locked to the new bit position. This field needs to be programmed during the PHY initialization routine before training sequences are received. The effect here is that pipe_rx_valid is not de-asserted upon re-alignment. When this bit is 0, pipe_rx_valid will be de-asserted upon loss of COMMA lock and subsequent re-alignment. Applies for PCIe Gen 1/2 and USB3.1 Gen 1 only. ()
  [9] PHY_PIPE_CMN_CTRL1_9 rw — Block alignment clear on EIOS : When set, upon receiving a PCIe EIOS, 128b/130b block alignment is reset regardless of Rx signal detect from the PMA (applies for PCIe Gen 3 only). ()
  [8] PHY_PIPE_CMN_CTRL1_8 rw — Comma alignment clear on EIOS : When set, upon receiving a PCIe EIOS, Comma Alignment is reset regardless of Rx signal detect from the PMA (applies for PCIe Gen 1/2 only). ()
  [7] PHY_PIPE_CMN_CTRL1_7 rw — Block alignment ignore Rx SigDetect : When set, 128b/13xb block alignment will not be reset due to loss of signal detection from the PMA (applies for PCIe Gen 3 and USB3.1 Gen 2 only). ()
  [6] PHY_PIPE_CMN_CTRL1_6 rw — Comma alignment ignore Rx SigDetect : When set, Comma alignment will not be reset due to loss of signal detection from the PMA (applies for PCIe Gen 1/2 and USB3.1 Gen 1 only). ()
  [5:4] PHY_PIPE_CMN_CTRL1_5_4 rw — Rx signal detect delay : Selects the number of clock cycles of delay to add to the PMA signal detect when the bit alignment blocks should be reset after losing signal. ()
  [1] PHY_PIPE_CMN_CTRL1_1 rw — RefClk disable override: 1 = overrides turning off reference clock receiver by forcing cmn_refclk_disable PMA input low. 0 = normal control of cmn_refclk_disable PMA input by PHY logic. ()
  [0] PHY_PIPE_CMN_CTRL1_0 rw — PHY RefClk enable input ingnore : 0 = ignore phy_en_refclk PHY input (forces low internally). 1 = phy_en_refclk_used as specified for controling enable/disable of cmn_refclk_Xp/mX. ()
0xC004 WIZ16B8M4CT2_PHY_PIPE_COM_LOCK_CFG2__PHY_PIPE_COM_LOCK_CFG1 reset 0x8204400 — PIPE comma lock configuration1 register ()
  [31:24] PHY_PIPE_COM_LOCK_CFG2_15_8 — PCIe PCS Comma lock count fast: The number of COMMA symbols that needs to be seen in the same bit position for the comma state machine to lock. This field is used while the PCS is in P0 state after an EIOS has been seen, ie detecting FTS
  [23:16] PHY_PIPE_COM_LOCK_CFG2_7_0 — PCIe PCS Comma lock count: The number of COMMA symbols that needs to be seen in the same bit position for the comma state machine to lock. This field is used while the PCS is transitioning back to the P0 power state.
  [15:12] PHY_PIPE_COM_LOCK_CFG1_15_12 — PCIe PCS Comma unlock count: The number of COMMA symbols that need to be seen in the wrong bit position before the comma alignment state machine will transition to RESYNC or LOS state
  [11:0] PHY_PIPE_COM_LOCK_CFG1_11_0 — PCIe PCS Comma full lock count: The number of COMMA symbols that need to be seen in the same bit position for the comma alignment state machine to lock. The field is used for initial reset lock.
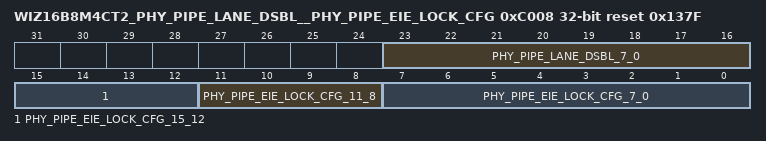
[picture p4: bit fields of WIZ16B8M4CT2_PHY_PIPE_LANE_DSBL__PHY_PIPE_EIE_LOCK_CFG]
0xC008 WIZ16B8M4CT2_PHY_PIPE_LANE_DSBL__PHY_PIPE_EIE_LOCK_CFG reset 0x137F — PIPE EIEOS lock configuration register ()
  [23:16] PHY_PIPE_LANE_DSBL_7_0 — PIPE lane disable: Each bit corresponds to a lane (i.e. bit [0] -X lane 0, bit [1] -X lane 1, etc). When set the corresponding PIPE lane is disabled. Lanes that are disabled will transmit electrical idle and will not return any data on PIPE Rx interface. Used to disable unused lanes in a multi-lane PCIe link. (The PMA transceiver corresponding to lane will be placed in suspend.)
  [15:12] PHY_PIPE_EIE_LOCK_CFG_15_12 — EIE lock count fast: The number of EIEOS blocks that need to be seen in the same bit postion for the alignment state machine to lock for Gen3/4. The field is used while the PCS is in P0 state after an EIEOS has been seen
  [11:8] PHY_PIPE_EIE_LOCK_CFG_11_8 — EIE lock count : The number of EIEOS blocks that need to be seen in the same bit postion for the alignment state machine to lock for Gen3/4. The field is used while the PCS is transitioning out of a power state change and not performing a rate change
  [7:0] PHY_PIPE_EIE_LOCK_CFG_7_0 — EIE full lock count: The number of EIEOS blocks that need to be seen in the same bit postion for the alignment state machine to lock for Gen3/4. The field is used for initial after reset lock or lock after a rate change
